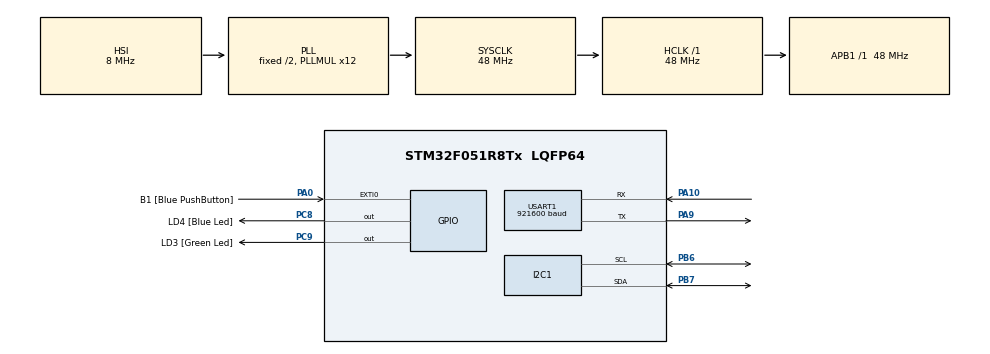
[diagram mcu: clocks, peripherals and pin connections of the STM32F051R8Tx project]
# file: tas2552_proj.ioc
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Dma.Request0=USART1_TX
Dma.Request1=USART1_RX
Dma.USART1_RX.1.Direction=DMA_PERIPH_TO_MEMORY
Dma.USART1_RX.1.Instance=DMA1_Channel3
Dma.USART1_RX.1.MemDataAlignment=DMA_MDATAALIGN_BYTE
Dma.USART1_RX.1.MemInc=DMA_MINC_ENABLE
Dma.USART1_RX.1.Mode=DMA_NORMAL
Dma.USART1_RX.1.PeriphDataAlignment=DMA_PDATAALIGN_BYTE
Dma.USART1_RX.1.PeriphInc=DMA_PINC_DISABLE
Dma.USART1_RX.1.Priority=DMA_PRIORITY_LOW
Dma.USART1_TX.0.Direction=DMA_MEMORY_TO_PERIPH
Dma.USART1_TX.0.Instance=DMA1_Channel2
Dma.USART1_TX.0.MemDataAlignment=DMA_MDATAALIGN_BYTE
Dma.USART1_TX.0.MemInc=DMA_MINC_ENABLE
Dma.USART1_TX.0.Mode=DMA_NORMAL
Dma.USART1_TX.0.PeriphDataAlignment=DMA_PDATAALIGN_BYTE
Dma.USART1_TX.0.PeriphInc=DMA_PINC_DISABLE
Dma.USART1_TX.0.Priority=DMA_PRIORITY_VERY_HIGH
FREERTOS.Tasks01=gateKeeper,2,128,gateKeeperTask,Default,NULL,Dynamic,NULL,NULL;rs232Server,-2,128,rs232ServerTask,Default,NULL,Dynamic,NULL,NULL;rs232Client,-2,128,rs232ClientTask,Default,NULL,Dynamic,NULL,NULL
FREERTOS.configUSE_MALLOC_FAILED_HOOK=1
FREERTOS.configUSE_TIMERS=1
Mcu.Family=STM32F0
Mcu.Name=STM32F051R8Tx
Mcu.Package=LQFP64
NVIC.DMA1_Channel2_3_IRQn=true\:3\:0\:false\:false\:true\:true\:false\:true
NVIC.TIM17_IRQn=true\:3\:0\:false\:false\:true\:false\:false\:true
NVIC.TimeBase=TIM17_IRQn
NVIC.TimeBaseIP=TIM17
NVIC.USART1_IRQn=true\:3\:0\:false\:false\:true\:true\:true\:true
PA0.GPIO_Label=B1 [Blue PushButton]
PA0.GPIO_ModeDefaultEXTI=GPIO_MODE_EVT_RISING
PA0.Signal=GPXTI0
PA10.Mode=Asynchronous
PA10.Signal=USART1_RX
PA13.GPIO_Label=SWDIO
PA13.Mode=Serial_Wire
PA13.Signal=SYS_SWDIO
PA14.GPIO_Label=SWCLK
PA14.Mode=Serial_Wire
PA14.Signal=SYS_SWCLK
PA9.Mode=Asynchronous
PA9.Signal=USART1_TX
PB6.Mode=I2C
PB6.Signal=I2C1_SCL
PB7.Mode=I2C
PB7.Signal=I2C1_SDA
PC8.GPIO_Label=LD4 [Blue Led]
PC8.Signal=GPIO_Output
PC9.GPIO_Label=LD3 [Green Led]
PC9.Signal=GPIO_Output
ProjectManager.HeapSize=0x200
ProjectManager.StackSize=0x400
ProjectManager.TargetToolchain=MDK-ARM V5.32
RCC.AHBFreq_Value=48000000
RCC.APB1Freq_Value=48000000
RCC.APB1TimFreq_Value=48000000
RCC.HCLKFreq_Value=48000000
RCC.PLLMUL=RCC_PLL_MUL12
RCC.SYSCLKFreq_VALUE=48000000
RCC.SYSCLKSource=RCC_SYSCLKSOURCE_PLLCLK
USART1.BaudRate=921600
USART1.VirtualMode-Asynchronous=VM_ASYNC
VP_FREERTOS_VS_CMSIS_V1.Mode=CMSIS_V1
VP_SYS_VS_tim17.Mode=TIM17
board=STM32F0DISCOVERY

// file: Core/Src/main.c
/* USER CODE BEGIN Header */
/**
  ******************************************************************************
  * @file           : main.c
  * @brief          : Main program body
  ******************************************************************************
  * @attention
  *
  * Copyright (c) 2022 STMicroelectronics.
  * All rights reserved.
  *
  * This software is licensed under terms that can be found in the LICENSE file
  * in the root directory of this software component.
  * If no LICENSE file comes with this software, it is provided AS-IS.
  *
  ******************************************************************************
  */
/* USER CODE END Header */
#include "main.h"
#include "cmsis_os.h"
#include "dma.h"
#include "i2c.h"
#include "usart.h"
#include "gpio.h"

/* USER CODE BEGIN Includes */
#include "comm_server.h"
#include "comm_client.h"
/* USER CODE END Includes */

void SystemClock_Config(void);
void MX_FREERTOS_Init(void);

int main(void)
{

  /* MCU Configuration--------------------------------------------------------*/

  /* Reset of all peripherals, Initializes the Flash interface and the Systick. */
  HAL_Init();

  /* Configure the system clock */
  SystemClock_Config();

  /* Initialize all configured peripherals */
  MX_GPIO_Init();
  MX_I2C1_Init();
  MX_DMA_Init();
  MX_USART1_UART_Init();

  /* Call init function for freertos objects (in freertos.c) */
  MX_FREERTOS_Init();
  /* Start scheduler */
  osKernelStart();

  /* We should never get here as control is now taken by the scheduler */
  /* Infinite loop */
    while (1) {

    }
}

void SystemClock_Config(void)
{
  RCC_OscInitTypeDef RCC_OscInitStruct = {0};
  RCC_ClkInitTypeDef RCC_ClkInitStruct = {0};
  RCC_PeriphCLKInitTypeDef PeriphClkInit = {0};

  /** Initializes the RCC Oscillators according to the specified parameters
  * in the RCC_OscInitTypeDef structure.
  */
  RCC_OscInitStruct.OscillatorType = RCC_OSCILLATORTYPE_HSI;
  RCC_OscInitStruct.HSIState = RCC_HSI_ON;
  RCC_OscInitStruct.HSICalibrationValue = RCC_HSICALIBRATION_DEFAULT;
  RCC_OscInitStruct.PLL.PLLState = RCC_PLL_ON;
  RCC_OscInitStruct.PLL.PLLSource = RCC_PLLSOURCE_HSI;
  RCC_OscInitStruct.PLL.PLLMUL = RCC_PLL_MUL12;
  RCC_OscInitStruct.PLL.PREDIV = RCC_PREDIV_DIV1;
  if (HAL_RCC_OscConfig(&RCC_OscInitStruct) != HAL_OK)
  {
    Error_Handler();
  }
  /** Initializes the CPU, AHB and APB buses clocks
  */
  RCC_ClkInitStruct.ClockType = RCC_CLOCKTYPE_HCLK|RCC_CLOCKTYPE_SYSCLK
                              |RCC_CLOCKTYPE_PCLK1;
  RCC_ClkInitStruct.SYSCLKSource = RCC_SYSCLKSOURCE_PLLCLK;
  RCC_ClkInitStruct.AHBCLKDivider = RCC_SYSCLK_DIV1;
  RCC_ClkInitStruct.APB1CLKDivider = RCC_HCLK_DIV1;

  if (HAL_RCC_ClockConfig(&RCC_ClkInitStruct, FLASH_LATENCY_1) != HAL_OK)
  {
    Error_Handler();
  }
  PeriphClkInit.PeriphClockSelection = RCC_PERIPHCLK_USART1|RCC_PERIPHCLK_I2C1;
  PeriphClkInit.Usart1ClockSelection = RCC_USART1CLKSOURCE_PCLK1;
  PeriphClkInit.I2c1ClockSelection = RCC_I2C1CLKSOURCE_HSI;
  if (HAL_RCCEx_PeriphCLKConfig(&PeriphClkInit) != HAL_OK)
  {
    Error_Handler();
  }
}

void HAL_TIM_PeriodElapsedCallback(TIM_HandleTypeDef *htim)
{
  if (htim->Instance == TIM17) {
    HAL_IncTick();
  }
}

void Error_Handler(void)
{
    __disable_irq();
    while (1) {
    }
}

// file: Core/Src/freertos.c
/* USER CODE BEGIN Header */
/**
  ******************************************************************************
  * File Name          : freertos.c
  * Description        : Code for freertos applications
  ******************************************************************************
  * @attention
  *
  * Copyright (c) 2022 STMicroelectronics.
  * All rights reserved.
  *
  * This software is licensed under terms that can be found in the LICENSE file
  * in the root directory of this software component.
  * If no LICENSE file comes with this software, it is provided AS-IS.
  *
  ******************************************************************************
  */
/* USER CODE END Header */

#include "FreeRTOS.h"
#include "task.h"
#include "main.h"
#include "cmsis_os.h"

/* USER CODE BEGIN Includes */
#include "stdio.h"
#include "usart.h"
#include "port_service.h"
#include "comm_server.h"
#include "comm_client.h"

#include "tas2552.h"
#include "rtos_comm_objects.h"
#include "app_service.h"
/* USER CODE END Includes */

osThreadId gateKeeperHandle;
osThreadId rs232ServerHandle;
osThreadId rs232ClientHandle;

void MX_FREERTOS_Init(void); /* (MISRA C 2004 rule 8.1) */

/* GetIdleTaskMemory prototype (linked to static allocation support) */
void vApplicationGetIdleTaskMemory(StaticTask_t **ppxIdleTaskTCBBuffer, StackType_t **ppxIdleTaskStackBuffer,
                                   uint32_t *pulIdleTaskStackSize);

/* GetTimerTaskMemory prototype (linked to static allocation support) */
void vApplicationGetTimerTaskMemory(StaticTask_t **ppxTimerTaskTCBBuffer, StackType_t **ppxTimerTaskStackBuffer,
                                    uint32_t *pulTimerTaskStackSize);

/* Hook prototypes */
void vApplicationMallocFailedHook(void);

/* USER CODE BEGIN 5 */
__weak void vApplicationMallocFailedHook(void) {
    /* vApplicationMallocFailedHook() will only be called if
    configUSE_MALLOC_FAILED_HOOK is set to 1 in FreeRTOSConfig.h. It is a hook
    function that will get called if a call to pvPortMalloc() fails.
    pvPortMalloc() is called internally by the kernel whenever a task, queue,
    timer or semaphore is created. It is also called by various parts of the
    demo application. If heap_1.c or heap_2.c are used, then the size of the
    heap available to pvPortMalloc() is defined by configTOTAL_HEAP_SIZE in
    FreeRTOSConfig.h, and the xPortGetFreeHeapSize() API function can be used
    to query the size of free heap space that remains (although it does not
    provide information on how the remaining heap might be fragmented). */
}
/* USER CODE END 5 */

/* USER CODE BEGIN GET_IDLE_TASK_MEMORY */
static StaticTask_t xIdleTaskTCBBuffer;
static StackType_t xIdleStack[configMINIMAL_STACK_SIZE];

void vApplicationGetIdleTaskMemory(StaticTask_t **ppxIdleTaskTCBBuffer, StackType_t **ppxIdleTaskStackBuffer,
                                   uint32_t *pulIdleTaskStackSize) {
    *ppxIdleTaskTCBBuffer = &xIdleTaskTCBBuffer;
    *ppxIdleTaskStackBuffer = &xIdleStack[0];
    *pulIdleTaskStackSize = configMINIMAL_STACK_SIZE;
    /* place for user code */
}
/* USER CODE END GET_IDLE_TASK_MEMORY */

/* USER CODE BEGIN GET_TIMER_TASK_MEMORY */
static StaticTask_t xTimerTaskTCBBuffer;
static StackType_t xTimerStack[configTIMER_TASK_STACK_DEPTH];

void vApplicationGetTimerTaskMemory(StaticTask_t **ppxTimerTaskTCBBuffer, StackType_t **ppxTimerTaskStackBuffer,
                                    uint32_t *pulTimerTaskStackSize) {
    *ppxTimerTaskTCBBuffer = &xTimerTaskTCBBuffer;
    *ppxTimerTaskStackBuffer = &xTimerStack[0];
    *pulTimerTaskStackSize = configTIMER_TASK_STACK_DEPTH;
    /* place for user code */
}
/* USER CODE END GET_TIMER_TASK_MEMORY */

void MX_FREERTOS_Init(void) {

    /* USER CODE BEGIN RTOS_QUEUES */
    /* add queues, ... */
//    init_comm_obj(TASK_SERVER, &rs232ServerHandle);
//    init_comm_obj(TASK_CLIENT, &rs232ClientHandle);
    /* USER CODE END RTOS_QUEUES */

    /* Create the thread(s) */
    /* definition and creation of gateKeeper */
    /* USER CODE BEGIN RTOS_THREADS */
    /* add threads, ... */
//    init_comm_obj(TASK_GATE_KEEPER, &gateKeeperHandle);
    initialize_port_service(PORT_QUEUE_SEND_MODE);

    init_comm_server_app();
    init_comm_client_app();
    init_service_app();

    /* USER CODE END RTOS_THREADS */

}
